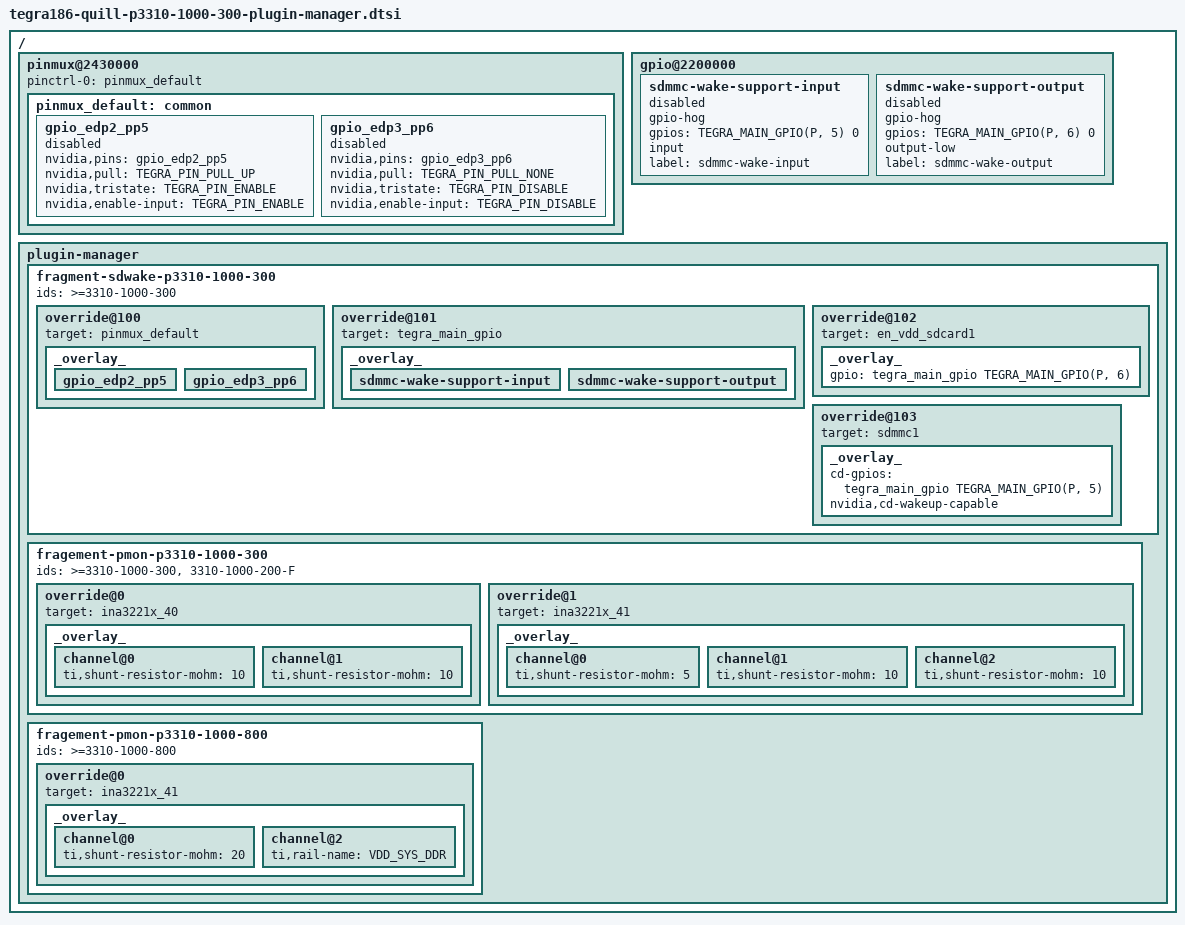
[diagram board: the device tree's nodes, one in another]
/*
 * Copyright (c) 2016, NVIDIA CORPORATION.  All rights reserved.
 *
 * This program is free software; you can redistribute it and/or modify
 * it under the terms of the GNU General Public License as published by
 * the Free Software Foundation; either version 2 of the License, or
 * (at your option) any later version.
 *
 * This program is distributed in the hope that it will be useful, but WITHOUT
 * ANY WARRANTY; without even the implied warranty of MERCHANTABILITY or
 * FITNESS FOR A PARTICULAR PURPOSE.  See the GNU General Public License for
 * more details.
 */

#include <dt-bindings/pinctrl/pinctrl-tegra.h>
#include <dt-bindings/gpio/tegra186-gpio.h>

/ {
	pinmux@2430000 {
		pinctrl-names = "default";
		pinctrl-0 = <&pinmux_default>;

		pinmux_default: common {
			gpio_edp2_pp5 {
				nvidia,pins = "gpio_edp2_pp5";
				nvidia,pull = <TEGRA_PIN_PULL_UP>;
				nvidia,tristate = <TEGRA_PIN_ENABLE>;
				nvidia,enable-input = <TEGRA_PIN_ENABLE>;
				status = "disabled";
			};

			gpio_edp3_pp6 {
				nvidia,pins = "gpio_edp3_pp6";
				nvidia,pull = <TEGRA_PIN_PULL_NONE>;
				nvidia,tristate = <TEGRA_PIN_DISABLE>;
				nvidia,enable-input = <TEGRA_PIN_DISABLE>;
				status = "disabled";
			};
		};
	};

	gpio@2200000 {
		sdmmc-wake-support-input {
			gpio-hog;
			gpios = <TEGRA_MAIN_GPIO(P, 5) 0>;
			input;
			label = "sdmmc-wake-input";
			status = "disabled";
		};

		sdmmc-wake-support-output {
			gpio-hog;
			gpios = <TEGRA_MAIN_GPIO(P, 6) 0>;
			output-low;
			label = "sdmmc-wake-output";
			status = "disabled";
		};
	};

	plugin-manager {
		fragment-sdwake-p3310-1000-300 {
			ids = ">=3310-1000-300";

			override@100 {
				target = <&pinmux_default>;
				_overlay_ {
					gpio_edp2_pp5 {
						status = "okay";
					};
					gpio_edp3_pp6 {
						status = "okay";
					};
				};
			};

			override@101 {
				target = <&tegra_main_gpio>;
				_overlay_ {
					sdmmc-wake-support-input {
						status = "okay";
					};
					sdmmc-wake-support-output {
						status = "okay";
					};
				};
			};

			override@102 {
				target = <&en_vdd_sdcard1>;
				_overlay_ {
					gpio = <&tegra_main_gpio TEGRA_MAIN_GPIO(P, 6) 0>;
				};
			};

			override@103 {
				target = <&sdmmc1>;
				_overlay_ {
					cd-gpios = <&tegra_main_gpio TEGRA_MAIN_GPIO(P, 5) 0>;
					nvidia,cd-wakeup-capable;
				};
			};
		};

		fragement-pmon-p3310-1000-300 {
			ids = ">=3310-1000-300", "3310-1000-200-F";
			override@0 {
				target = <&ina3221x_40>;
				_overlay_ {
					channel@0 {
						ti,shunt-resistor-mohm = <10>;
					};
					channel@1 {
						ti,shunt-resistor-mohm = <10>;
					};
				};
			};

			override@1 {
				target = <&ina3221x_41>;
				_overlay_ {
					channel@0 {
						ti,shunt-resistor-mohm = <5>;
					};
					channel@1 {
						ti,shunt-resistor-mohm = <10>;
					};
					channel@2 {
						ti,shunt-resistor-mohm = <10>;
					};
				};
			};
		};
		fragement-pmon-p3310-1000-800 {
			ids = ">=3310-1000-800";
			override@0 {
				target = <&ina3221x_41>;
				_overlay_ {
					channel@0 {
						ti,shunt-resistor-mohm = <20>;
					};
					channel@2 {
						ti,rail-name = "VDD_SYS_DDR";
					};
				};
			};
		};

	};
};
